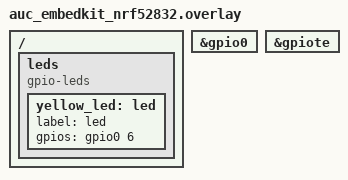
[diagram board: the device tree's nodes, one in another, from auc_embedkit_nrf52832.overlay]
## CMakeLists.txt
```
cmake_minimum_required(VERSION 3.20.0)
find_package(Zephyr REQUIRED HINTS $ENV{ZEPHYR_BASE})

project(L1)

target_sources(app PRIVATE src/main.c)
```

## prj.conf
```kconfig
# includes the GPIO driver (enable the inclusion of the source code of the GPIO driver
#  into the build process and hence our application will be able to use it.)
CONFIG_GPIO=y

# enable including of the console drivers 
CONFIG_CONSOLE=y

# Enable Segger J-Link RTT libraries for platforms that support it. 
# Selection of this option enables use of RTT for various subsystems. Note that by enabling this option, 
# RTT buffers consume more RAM.
CONFIG_USE_SEGGER_RTT=y

# Emit console messages to a RAM buffer that is then read by the Segger J-Link software and displayed on a computer in real-time. 
# Requires support for Segger J-Link on the companion IC onboard.
CONFIG_RTT_CONSOLE=y
```

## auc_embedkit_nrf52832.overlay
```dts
// To get started, press Ctrl+Space to bring up the completion menu and view the available nodes.

// You can also use the buttons in the sidebar to perform actions on nodes.
// Actions currently available include:

// * Enabling / disabling the node
// * Adding the bus to a bus
// * Removing the node
// * Connecting ADC channels

// For more help, browse the DeviceTree documentation at https://docs.zephyrproject.org/latest/guides/dts/index.html
// You can also visit the nRF DeviceTree extension documentation at https://docs.nordicsemi.com/bundle/nrf-connect-vscode/page/guides/ncs_configure_app.html#devicetree-support-in-the-extension

&gpio0 {
	status = "okay";
};

&gpiote {
	status = "okay";
};


/ {
	leds {
		compatible = "gpio-leds";
		yellow_led: led {
			label = "led";
			gpios = <&gpio0 6 0>;
		};
	};

};
```

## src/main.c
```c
// have some useful utility functions provided by zeyphr kernal.
#include <zephyr/kernel.h>

// include the GPIO driver
#include <zephyr/drivers/gpio.h>

// include the printk function header 
#include <zephyr/sys/printk.h>

// get the gpio pin properties from the .overlay file
// static struct gpio_dt_spec led = GPIO_DT_SPEC_GET(DT_NODELABEL(yellow_led), gpios);
static const struct gpio_dt_spec led = GPIO_DT_SPEC_GET(DT_NODELABEL(yellow_led), gpios);


int main(void)
{
	
	// a variable to keep track of the led 
	int led_state = 0;

	// check if the pin is ready to use (the function returns 0 if everything is ok)
	if(!gpio_is_ready_dt(&led))
	{
		// end the program
		return 0;
	}

	// check if the pin is configured successfully (the function returns 0 if everything is ok)
	if(gpio_pin_configure_dt(&led, GPIO_OUTPUT_INACTIVE) < 0)
	{
		// end the program
		return 0;
	}

	// loop infinitely
	while(1)
	{
		// print led state
		printk("LED state = %d\n\r", led_state);
		led_state = !led_state;

		// toggle the led and check if it was toggled successfully 
		if(gpio_pin_toggle_dt(&led) < 0)
		{
				return 0;
		}

		// sleep for 1 second 
		k_msleep(1000);
	}

	return 0;
}
```
